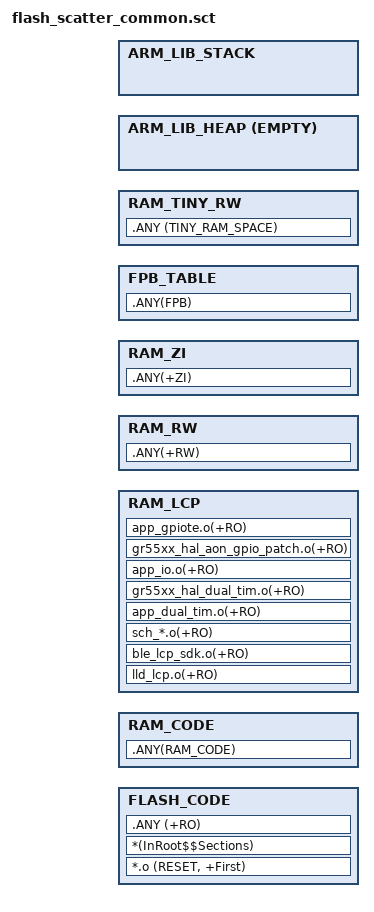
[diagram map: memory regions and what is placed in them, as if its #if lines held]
#! armcc -E -I .\..\Src\user\ -I .\..\Src\config\ --cpu Cortex-M4

#include "flash_scatter_config.h"
#define ALIGN_DWORD 0x0008
#define ALIGN_WORD  0x0004
#define ALIGN_16KB  0x4000
#define ALIGN_32KB  0x8000

; *************************************************************
; *** Scatter-Loading Description File generated by uVision ***
; *************************************************************
;
; If an application uses a different memory layout then it must
; use a customized scatter file.
;**************************************************************

LR_FLASH APP_CODE_RUN_ADDR FLASH_SIZE {
    ; Flash layout
    FLASH_CODE APP_CODE_RUN_ADDR APP_MAX_CODE_SIZE {  ; load address = execution address
        *.o (RESET, +First)
        *(InRoot$$Sections)
        .ANY (+RO)
    }

    #if defined(XIP_MODE)
    ; Ram code space AREA
    RAM_CODE (RAM_CODE_SPACE_START) RAM_CODE_SPACE_SIZE {
        .ANY(RAM_CODE)
    }
    #endif
    #if (CFG_LCP_SUPPORT)
    ; retention RAM for LCP Module
    RAM_LCP AlignExpr(+0, ALIGN_WORD) CRITICAL_CODE_MAX_SIZE {
        lld_lcp.o(+RO)
        ble_lcp_sdk.o(+RO)
        sch_*.o(+RO)
        app_dual_tim.o(+RO)
        gr55xx_hal_dual_tim.o(+RO)
        app_io.o(+RO)
        gr55xx_hal_aon_gpio_patch.o(+RO)
        app_gpiote.o(+RO)
    }
    #endif

    #if defined(HMIRROR_MODE)
    ; Ram data
    RAM_RW (+0) APP_RAM_SIZE {
        .ANY(+RW)
    }
    RAM_ZI (+0) APP_RAM_SIZE {
        .ANY(+ZI)
    }
    #else
    ; Ram data
    RAM_RW (+HIGH_RAM_OFFSET) APP_RAM_SIZE {
        .ANY(+RW)
    }
    RAM_ZI (+0) APP_RAM_SIZE {
        .ANY(+ZI)
    }
    #endif

    ; FPB space
    FPB_TABLE AlignExpr(+0, 128) FPB_DATA_SPACE_SIZE {
        .ANY(FPB)
    }
    RAM_TINY_RW TINY_RAM_SPACE_START TINY_RAM_SPACE_SIZE {
        .ANY (TINY_RAM_SPACE)
    }
    ; Ram heap
    ARM_LIB_HEAP  AlignExpr(STACK_END_ADDR - SYSTEM_HEAP_SIZE - SYSTEM_STACK_SIZE, ALIGN_DWORD) EMPTY SYSTEM_HEAP_SIZE {}
    ; Ram stack
    ARM_LIB_STACK AlignExpr(STACK_END_ADDR, ALIGN_DWORD) EMPTY - SYSTEM_STACK_SIZE {}
}
